# MMCSD2_CTL_CFG register map
Vendor: Texas Instruments
Registers are 16-bit, read-only, reset 0x0 unless marked. A register's access mark holds for its fields unless they carry their own. Offsets are as the file gives them; [hi:lo] are bit positions; lines under a group give offsets from that group.

## MMCSD2_CTL_CFG (part 3 of 3)
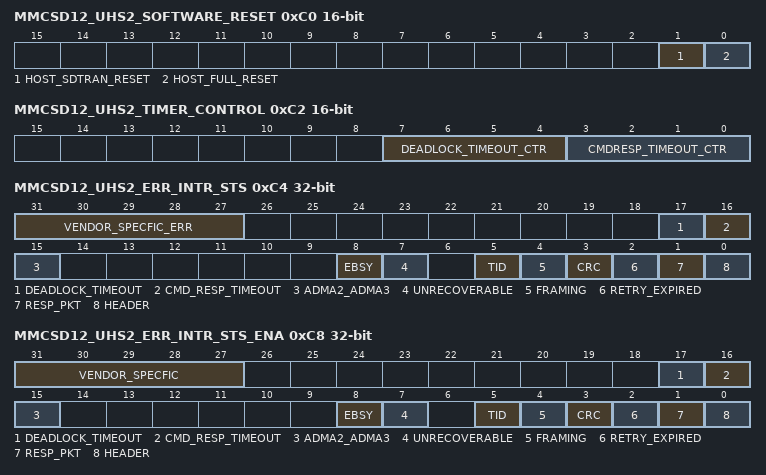
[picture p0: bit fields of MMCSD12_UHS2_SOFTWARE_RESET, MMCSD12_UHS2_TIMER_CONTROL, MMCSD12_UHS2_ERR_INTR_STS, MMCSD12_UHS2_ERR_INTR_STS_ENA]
0xC0 MMCSD12_UHS2_SOFTWARE_RESET access per field — UHS-II Software Reset Register.
  [1] HOST_SDTRAN_RESET rw — Host SD-TRAN Reset Host Driver set this bit to 1h to reset SD-TRAN layer when CMD0 is issued to Device or data transfer error occurs. This bit is cleared automatically at completion of SD-TRAN reset. If CMD0 is issued, SD-TRAN Initialization sequence from CMD8 is required to use UHS-II mode. Assuming that bus power is maintained and CM-TRAN Initialization is not required. Host Controller requires to do followings: (1) SD Clock Enable is maintained (continue to provide RCLK). (2) All setting register is maintained. (3) Internal sequencers are reset to just after power on be able to issue a command. (4) All Interrupt Status, Status Enable and Signal Enable are cleared. (5) Data transfer is terminated and data in buffer is discarded. 0h: Not Affected 1h: Reset SD-TRAN
  [0] HOST_FULL_RESET rw — Host Full Reset On issuing FULL_RESET CCMD, Host Driver set this bit to 1h to reset Host Controller. This bit is cleared automatically at completion of Host Controller reset. Initialization sequence from PHY Initialization is required to use UHS-II mode. Assuming that bus power is maintained. Host Controller requires to do followings: (1) SD Clock Enable is cleared (internal Clock is still synchronized). (2) All setting register is cleared. (3) Internal sequencers are reset to just after power on. (4) All Interrupt Status, Status Enable and Signal Enable are cleared. 0h: Not Affected 1h: Reset Host Controller
0xC2 MMCSD12_UHS2_TIMER_CONTROL access per field — UHS-II Timeout Control Register.
  [7:4] DEADLOCK_TIMEOUT_CTR rw — Timeout Counter Value for Deadlock This value determines the deadlock period while host expecting to receive a packet (1 second). Timeout clock frequency will be generated by dividing the base clock TMCLK value by this value. When setting this register, prevent inadvertent timeout events by clearing the Timeout for Deadlock (in the Fh: Reserved Eh: TMCLK x 2 .... .... 1h: TMCLK x 2 0h: TMCLK x 2
  [3:0] CMDRESP_TIMEOUT_CTR rw — Timeout Counter Value for CMD_RES This value determines the interval between command packet and response packet (5 ms). Timeout clock frequency will be generated by dividing the base clock TMCLK value by this value. When setting this register, prevent inadvertent timeout events by clearing the Timeout for CMD_RES (in the Fh: Reserved Eh: TMCLK x 2 .... .... 1h: TMCLK x 2 0h: TMCLK x 2
0xC4 MMCSD12_UHS2_ERR_INTR_STS 32-bit access not given — This register gives the status of all UHS-II interrupts.
  [31:27] VENDOR_SPECFIC_ERR — Vendor Specific Error Vendor may use this field for vendor specific error status. 0h: Interrupt is not generated 1h: Vendor Specific Error (access RW1C)
  [17] DEADLOCK_TIMEOUT — Timeout for Deadlock Setting of this bit means that deadlock timeout occurs. Host expects to receive a packet but not received in a specified timeout (1 second). Timeout value is determined by the setting of the 0h: Interrupt is not generated 1h: Deadlock Error (access RW1C)
  [16] CMD_RESP_TIMEOUT — Timeout for CMD_RES Setting of this bit means that RES Packet timeout occurs. Host expects to receive RES packet but not received in a specified timeout (5 ms). Timeout value is determined by the setting of the 0h: Interrupt is not generated 1h: RES Packet Timeout Error (access RW1C)
  [15] ADMA2_ADMA3 — ADMA2/3 Error Setting of this bit means that ADMA2/3 Error occurs in UHS-II mode. ADMA2/3 Error Status is indicated to the 0h: Interrupt is not generated 1h: ADMA2/3 Error (access RW1C)
  [8] EBSY — EBSY Error On receiving EBSY packet, if the packet indicates an error, this bit is set to 1h. Setting of this bit also sets Error Interrupt and Transfer Completer together in the 0h: Interrupt is not generated 1h: EBSY Error (Backend Error) (access RW1C)
  [7] UNRECOVERABLE — Unrecoverable Error Setting of this bit means that Unrecoverable Error is set in a packet from a device. 0h: Interrupt is not generated 1h: Device Unrecoverable Error (access RW1C)
  [5] TID — TID Error Setting of this bit means that TID Error occurs. 0h: Interrupt is not generated 1h: TID Error (access RW1C)
  [4] FRAMING — Framing Error Setting of this bit means that Framing Error occurs during a packet receiving. 0h: Interrupt is not generated 1h: Framing Error (access RW1C)
  [3] CRC — CRC Error Setting of this bit means that CRC Error occurs during a packet receiving. 0h: Interrupt is not generated 1h: CRC Error (access RW1C)
  [2] RETRY_EXPIRED — Retry Expired Setting of this bit means that Retry Counter Expired Error occurs during data transfer. If this bit is set, either Framing Error or CRC Error in this register shall be set. 0h: Interrupt is not generated 1h: Retry Expired Error (access RW1C)
  [1] RESP_PKT — RES Packet Error Host Controller Version 4.00 supports response error check function to avoid overhead of response error check by Host Driver during DMA execution. If the 0h: Interrupt is not generated 1h: RES Packet Error (access RW1C)
  [0] HEADER — Header Error Setting of this bit means that Header Error occurs in a received packet. 0h: Interrupt is not generated 1h: Header Error (access RW1C)
0xC8 MMCSD12_UHS2_ERR_INTR_STS_ENA 32-bit access per field — This register is used to enable the register fields.
  [31:27] VENDOR_SPECFIC rw — Vendor Specific Error Setting this bit to 1h enables setting of Vendor Specific Error bit in the 0h: Status is Disabled 1h: Status is Enabled
  [17] DEADLOCK_TIMEOUT rw — Timeout for Deadlock Setting this bit to 1h enables setting of Timeout for Dead lock bit in the 0h: Status is Disabled 1h: Status is Enabled
  [16] CMD_RESP_TIMEOUT rw — Timeout for CMD_RES Setting this bit to 1h enables setting of Timeout for CMD_RES bit in the 0h: Status is Disabled 1h: Status is Enabled
  [15] ADMA2_ADMA3 rw — ADMA2/3 Error Setting this bit to 1h enables setting of ADMA2/3 Error bit in the 0h: Status is Disabled 1h: Status is Enabled
  [8] EBSY rw — EBSY Error Setting this bit to 1h enables setting of EBSY Error bit in the 0h: Status is Disabled 1h: Status is Enabled
  [7] UNRECOVERABLE rw — Unrecoverable Error Setting this bit to 1h enables setting of Unrecoverable Error bit in the 0h: Status is Disabled 1h: Status is Enabled
  [5] TID rw — TID Error Setting this bit to 1h enables setting of TID Error bit in the 0h: Status is Disabled 1h: Status is Enabled
  [4] FRAMING rw — Framing Error Setting this bit to 1h enables setting of Framing Error bit in the 0h: Status is Disabled 1h: Status is Enabled
  [3] CRC rw — CRC Error Setting this bit to 1h enables setting of CRC Error bit in the 0h: Status is Disabled 1h: Status is Enabled
  [2] RETRY_EXPIRED rw — Retry Expired Setting this bit to 1h enables setting of Retry Expired bit in the 0h: Status is Disabled 1h: Status is Enabled
  [1] RESP_PKT rw — RES Packet Error Setting this bit to 1h enables setting of RES Packet Error bit in the 0h: Status is Disabled 1h: Status is Enabled
  [0] HEADER rw — Header Error Setting this bit to 1h enables setting of Header Error bit in the 0h: Status is Disabled 1h: Status is Enabled
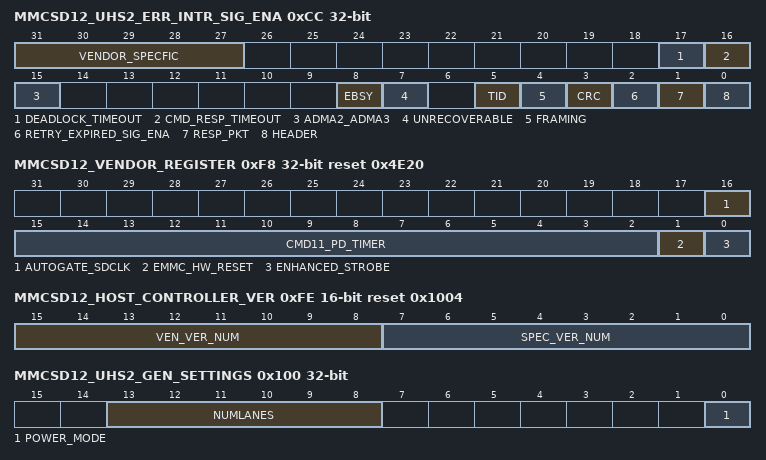
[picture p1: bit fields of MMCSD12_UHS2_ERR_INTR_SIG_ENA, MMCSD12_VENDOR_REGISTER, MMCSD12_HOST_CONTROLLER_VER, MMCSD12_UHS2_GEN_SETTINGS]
0xCC MMCSD12_UHS2_ERR_INTR_SIG_ENA 32-bit access per field — This register is used to generate UHS-II Interrupt signals.
  [31:27] VENDOR_SPECFIC rw — Vendor Specific Error Setting of a bit to 1h in this field enables generating interrupt signal when correspondent bit of Vendor Specific Error is set in the 0h: Interrupt Signal is Disabled 1h: Interrupt Signal is Enabled
  [17] DEADLOCK_TIMEOUT rw — Timeout for Deadlock Setting this bit to 1h enables generating interrupt signal when Timeout for Dead lock bit is set in the 0h: Interrupt Signal is Disabled 1h: Interrupt Signal is Enabled
  [16] CMD_RESP_TIMEOUT rw — Timeout for CMD_RES Setting this bit to 1h enables generating interrupt signal when Timeout for CMD_RES bit is set in the 0h: Interrupt Signal is Disabled 1h: Interrupt Signal is Enabled
  [15] ADMA2_ADMA3 rw — ADMA2/3 Error Setting this bit to 1h enables generating interrupt signal when ADMA2/3 Error bit is set in the 0h: Interrupt Signal is Disabled 1h: Interrupt Signal is Enabled
  [8] EBSY rw — EBSY Error Setting this bit to 1h enables generating interrupt signal when EBSY Error bit is set in the 0h: Interrupt Signal is Disabled 1h: Interrupt Signal is Enabled
  [7] UNRECOVERABLE rw — Unrecoverable Error Setting this bit to 1h enables generating interrupt signal when Unrecoverable Error bit is set in the 0h: Interrupt Signal is Disabled 1h: Interrupt Signal is Enabled
  [5] TID rw — TID Error Setting this bit to 1h enables generating interrupt signal when TID Error bit is set in the 0h: Interrupt Signal is Disabled 1h: Interrupt Signal is Enabled
  [4] FRAMING rw — Framing Error Setting this bit to 1h enables generating interrupt signal when Framing Error bit is set in the 0h: Interrupt Signal is Disabled 1h: Interrupt Signal is Enabled
  [3] CRC rw — CRC Error Setting this bit to 1h enables generating interrupt signal when CRC Error bit is set in the 0h: Interrupt Signal is Disabled 1h: Interrupt Signal is Enabled
  [2] RETRY_EXPIRED_SIG_ENA rw — Retry Expired Setting this bit to 1h enables generating interrupt signal when Retry Expired bit is set in the 0h: Interrupt Signal is Disabled 1h: Interrupt Signal is Enabled
  [1] RESP_PKT rw — RES Packet Error Setting this bit to 1h enables generating interrupt signal when RES Packet Error bit is set in the 0h: Interrupt Signal is Disabled 1h: Interrupt Signal is Enabled
  [0] HEADER rw — Header Error Setting this bit to 1h enables generating interrupt signal when Header Error bit is set in the 0h: Interrupt Signal is Disabled 1h: Interrupt Signal is Enabled
0xE0 MMCSD12_UHS2_SETTINGS_PTR reset 0x100 — This register is pointer for UHS-II settings.
  [15:0] UHS2_SETTINGS_PTR — Pointer for UHS-II Settings Register
0xE2 MMCSD12_UHS2_CAPABILITIES_PTR reset 0x110 — This register is pointer for UHS-II Capabilities Register.
  [15:0] UHS2_CAPABILITIES_PTR — Pointer for UHS-II Capabilities Register
0xE4 MMCSD12_UHS2_TEST_PTR reset 0x120 — This register is pointer for UHS-II Test Register.
  [15:0] UHS2_TEST_PTR — Pointer for UHS-II Test Register
0xE6 MMCSD12_SHARED_BUS_CTRL_PTR reset 0x130 — This register is pointer for UHS-II Shared Bus Control Register.
  [15:0] SHARED_BUS_CTRL_PTR — Pointer for Shared Bus Control Register
0xE8 MMCSD12_VENDOR_SPECFIC_PTR reset 0x140 — This register is pointer for UHS-II Vendor Specific Register.
  [15:0] VENDOR_SPECFIC_PTR — Pointer for Vendor Specific Area
0xF4 MMCSD12_BOOT_TIMEOUT_CONTROL 32-bit rw — This is used to program the boot timeout value counter.
  [31:0] DATA_TIMEOUT_CNT — Boot Data Timeout Counter Value This value determines the interval by which DAT line timeouts are detected during boot operation for eMMC4.4 card. The value is in number of SD clock.
0xF8 MMCSD12_VENDOR_REGISTER 32-bit access per field reset 0x4E20 — Vendor register added for Auto Gate SD CLK, CMD11 Power Down Timer, Enhanced Strobe and eMMC Hardware Reset.
  [16] AUTOGATE_SDCLK rw — Auto Gate SD CLK If this bit is set, SD CLK will be gated automatically when there is no transfer. This is applicable only for Embedded Device. 0h: Disable 1h: Enable
  [15:2] CMD11_PD_TIMER rw — CMD11 Power Down Timer Value
  [1] EMMC_HW_RESET rw — eMMC Hardware Reset Hardware reset signal is generared for eMMC card when this bit is set. 0h: De-sassert hardware reset pin 1h: Drives the hardware reset pin as ZERO (Active LOW to eMMC card)
  [0] ENHANCED_STROBE rw — Enhanced Strobe This bit enables the enhanced strobe logic of the Host Controller.
0xFC MMCSD12_SLOT_INT_STS — This register is used to read the interrupt signal for each slot.
  [7:0] INTR_SIG — Interrupt Signal for Slot#0 These status bits indicate the logical OR of Interrupt signal and Wakeup signal for each slot.
0xFE MMCSD12_HOST_CONTROLLER_VER reset 0x1004 — This register is used to read the vendor version number and specification version number.
  [15:8] VEN_VER_NUM — Vendor Version Number The Vendor Version Number is set to 10h (1.0)
  [7:0] SPEC_VER_NUM — Specification Version Number This status indicates the Host Controller Specification Version. The upper and lower 4-bits indicate the version. 0h: SD Host Controller Specification Version 1.00 1h: SD Host Controller Specification Version 2.00 Including the feature of the ADMA and Test Register 2h: SD Host Controller Specification Version 3.00 3h: SD Host Controller Specification Version 4.00 4h: SD Host Controller Specification Version 4.10 Others: Reserved
0x100 MMCSD12_UHS2_GEN_SETTINGS 32-bit access per field — Start Address of General settings is pointed by the Register.
  [13:8] NUMLANES rw — Number of Lanes and Functionalities The lane configuration of a Host System is set to this field depends on the capability among Host Controller and connected devices. 2 Lanes FD mode is mandatory and the others modes are optional. 0h: 2 Lanes FD or 2L-HD 1h: Not Used 2h: 3 Lanes 2D1U-FD (Embedded) 3h: 3 Lanes 1D2U-FD (Embedded) 4h: 4 Lanes 2D2U-FD (Embedded) Others: Reserved
  [0] POWER_MODE rw — Power Mode This field determines either Fast mode or Low Power mode. Host and all devices connected to the host shall be set to the same mode. 0h: Fast Mode 1h: Low Power Mode
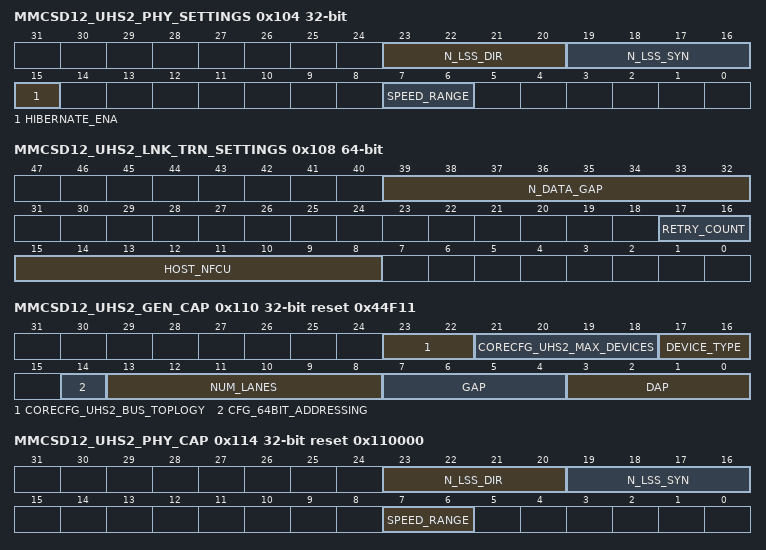
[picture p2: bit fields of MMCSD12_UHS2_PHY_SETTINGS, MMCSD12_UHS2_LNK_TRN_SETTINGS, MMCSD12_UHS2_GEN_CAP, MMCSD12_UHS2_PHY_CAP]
0x104 MMCSD12_UHS2_PHY_SETTINGS 32-bit access per field — Start Address of PHY settings is pointed by the Register.
  [23:20] N_LSS_DIR rw — Host N_LSS_DIR The largest value of N_LSS_DIR capabilities among the Host Controller and Connected Devices is set to this field. 0h: 8 x 16 LSS 1h: 8 x 1 LSS 2h: 8 x 2 LSS 3h: 8 x 3 LSS .... .... Fh: 8 x 15 LSS
  [19:16] N_LSS_SYN rw — Host N_LSS_SYN The largest value of N_LSS_SYN capabilities among the Host Controller and Connected Devices is set to this field. 0h: 4 x 16 LSS 1h: 4 x 1 LSS 2h: 4 x 2 LSS 3h - 4 x 3 LSS .... .... Fh: 4 x 15 LSS
  [15] HIBERNATE_ENA rw — Hibernate Enable After checking card capability of Hibernate mode, if all devices support Hibernate mode, this bit may be set. This bit determines whether Host remains in Dormant state or goes to Hibernate state. In Hibernate mode, VDD1 Power may be off. 0h: Hibernate Disabled 1h: Hibernate Enabled
  [7:6] SPEED_RANGE rw — Speed Range PLL multiplier is selected by this field. Change of PLL Multiplier is not effective immediately and is applied from exiting Dormant State. 0h: Range A (Defalt) 1h: Range B 2h: Reserved 3h: Reserved
0x108 MMCSD12_UHS2_LNK_TRN_SETTINGS 64-bit access per field — Start Address of LINK/TRAN settings is pointed by the Register.
  [39:32] N_DATA_GAP rw — Host N_DATA_GAP The largest value of N_DATA_GAP capabilities among the Host Controller and Connected Devices is set to this field. 00h: No Gap 01h: 1 LSS 02h: 2 LSS 03h: 3 LSS .... .... FFh: 255 LSS
  [17:16] RETRY_COUNT rw — Retry Count Data Burst retry count is set to this field. 00h: Retry Disabled 01h: 1 time 02h: 2 times 03h: 3 times
  [15:8] HOST_NFCU rw — Host N_FCU Host Driver sets the number of blocks in Data Burst (Flow Control) to this field. The value shall be smaller than or equal to N_FCU capabilities among the Host Controller and connected card and devices. Setting 1 to 4 blocks is recommended considering buffer size. 00h: 256 Blocks 01h: 1 Block 02h: 2 Blocks 03h: 3 Blocks .... .... FFh: 255 Blocks
0x110 MMCSD12_UHS2_GEN_CAP 32-bit reset 0x44F11 — Start Address of General Capabilities is pointed by the Register.
  [23:22] CORECFG_UHS2_BUS_TOPLOGY — Bus Topology This field indicates one of bus topologies configured by a Host system. 0h: P2P Connection 1h: Ring Connection 2h: HUB Connection 3h: HUB is Connected in Ring
  [21:18] CORECFG_UHS2_MAX_DEVICES — Number of Devices Supported This field indicates the maximum number of devices supported by the Host Controller. 0h: Not used 1h: 1 Devices 2h: 2 Devices .... .... Fh: 15 Devices
  [17:16] DEVICE_TYPE — Removable/Embedded This field indicates device type configured by a Host system. 0h: Removable Card (P2P) 1h: Embedded Devices 2h: Embedded Devices + Removable Card 3h: Reserved
  [14] CFG_64BIT_ADDRESSING — 64-bit Addressing This field indicates support of 64-bit addressing by the Host Controller. 0h: 32-bit Addressing is supported 1h: 32-bit and 64-bit Addressing is supported
  [13:8] NUM_LANES — Number of Lanes and Functionalities This field indicates support of lanes by the Host Controller. 0 mean not supported and 1 means supported. D08: 2L-HD D09: 2D1U-FD D10: 1D2U-FD D11: 2D2U-FD D12: Reserved D13: Reserved
  [7:4] GAP — GAP (Group Allocation Power) This field indicates the maximum capability of host power supply for a group configured by a Host system. This field is used to set the argument of DEVICE_INIT CCM. 0h: Not used 1h: 360 mW 2h: 720 mW .... .... Fh: 360 x 15 mW
  [3:0] DAP — DAP (Device Allocation Power) This field indicates the maximum capability of host power supply for a device configured by a Host system. This field is used to set the argument of DEVICE_INIT CCMD. 0h: 360 mW (Default) 1h: 360 mW 2h: 720 mW .... .... Fh: 360 x 15 mW
0x114 MMCSD12_UHS2_PHY_CAP 32-bit reset 0x110000 — Start Address of PHY Capabilities is pointed by the Register.
  [23:20] N_LSS_DIR — Host N_LSS_DIR This field indicates the minimum N_LSS_DIR required by the Host Controller. 0h: 4 x 16 LSS 1h: 4 x 1 LSS 2h: 4 x 2 LSS 3h: 4 x 3 LSS .... .... Fh: 4 x 15 LSS
  [19:16] N_LSS_SYN — Host N_LSS_SYN This field indicates the minimum N_LSS_SYN required by the Host Controller. 0h: 4 x 16 LSS 1h: 4 x 1 LSS 2h: 4 x 2 LSS 3h: 4 x 3 LSS .... .... Fh: 4 x 15 LSS
  [7:6] SPEED_RANGE — Speed Range This field indicates supported Speed Range by the Host Controller. 0h: Range A (Default) 1h: Range A and Range B 2h: Reserved 3h: Reserved
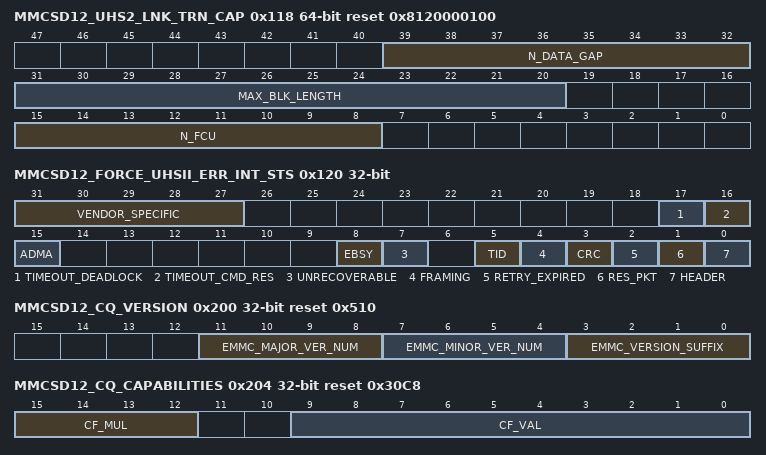
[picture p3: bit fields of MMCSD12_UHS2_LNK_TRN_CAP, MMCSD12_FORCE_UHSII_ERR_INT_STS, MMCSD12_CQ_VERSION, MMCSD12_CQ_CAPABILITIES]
0x118 MMCSD12_UHS2_LNK_TRN_CAP 64-bit reset 0x8120000100 — Start Address of LINK/TRAN settings is pointed by the Register.
  [39:32] N_DATA_GAP — Host N_DATA_GAP This field indicates the minimum number of data gap (DIDL) supported by the Host Controller. 00h: No Gap 01h: 1 LSS 02h: 2 LSS 03h: 3 LSS .... .... FFh: 255 LSS
  [31:20] MAX_BLK_LENGTH — Host Maximum Block Length This field indicates maximum block length by the Host Controller. 000h: Not Used 001h: 1 byte 002h: 2 bytes .... .... 200h: 512 bytes .... .... 800h: 2048 bytes 801h - FFFh: Not Used
  [15:8] N_FCU — Host N_FCU This field indicates maximum the number of blocks in a Flow Control unit by the Host Controller. This value is determined by supported buffer size. 00h: 256 Blocks 01h: 1 Block 02h: 2 Block 03h: 3 Block .... .... FFh: 255 Blocks
0x120 MMCSD12_FORCE_UHSII_ERR_INT_STS 32-bit access per field — This register is not physically implemented, rather it is an address where the register can be written.
  [31:27] VENDOR_SPECIFIC wo — Force Event for Vendor Specific Error 0h: Not Affected 1h: Vendor Specific Error Status is set
  [17] TIMEOUT_DEADLOCK wo — Force Event for Timeout for Deadlock Setting this bit forces the Host Controller to set Timeout for Deadlock in the 0h: Not affected 1h: Timeout for Deadlock Error status is set
  [16] TIMEOUT_CMD_RES wo — Force Event for Timeout for CMD_RES Setting this bit forces the Host Controller to set Timeout for CMD_RES in the 0h: Not affected 1h: Timout for CMD_RES Status is set
  [15] ADMA wo — Force Event for ADMA Error Setting this bit forces the Host Controller to set ADMA Error in the 0h: Not affected 1h: ADMA Error Status is set
  [8] EBSY wo — Force Event for EBSY Error Setting this bit forces the Host Controller to set EBSY Error in the 0h: Not affected 1h: EBSY Error Status is set
  [7] UNRECOVERABLE wo — Force Event for Unrecoverable Error Setting this bit forces the Host Controller to set Unrecoverable Error in the 0h: Not affected 1h: Unrecoverable Error Status is set
  [5] TID wo — Force Event for TID Error Setting this bit forces the Host Controller to set TID Error in the 0h: Not affected 1h: TID Error Status is set
  [4] FRAMING wo — Force Event for Framing Error Setting this bit forces the Host Controller to set Framing Error in the 0h: Not affected 1h: Framing Error Status is set
  [3] CRC wo — Force Event for CRC Error Setting this bit forces the Host Controller to set CRC Error in the 0h: Not affected 1h: CRC Error Status is set
  [2] RETRY_EXPIRED wo — Force Event for Retry Expired Setting this bit forces the Host Controller to set Retry Expired in the 0h: Not affected 1h: Retry expired error status is set
  [1] RES_PKT wo — Force Event for RES Packet Error Setting this bit forces the Host Controller to set RES Packet Error in the 0h: Not affected 1h: RES packet error status is set
  [0] HEADER wo — Force Event for Header Error Setting this bit forces the Host Controller to set Header Error in the 0h: Not affected 1h: Header error status is set
0x200 MMCSD12_CQ_VERSION 32-bit reset 0x510 — This register provides information about the version of the eMMC CQ (Command Queueing) standard which is 285 implemented by the CQE, in BCD format. The current version is rev 5.1. The following table describes the CQBASE+00h: Command Queueing Version.
  [11:8] EMMC_MAJOR_VER_NUM — eMMC Major Version Number (digit left of decimal point), in BCD format
  [7:4] EMMC_MINOR_VER_NUM — eMMC Minor Version Number (digit right of decimal point), in BCD format
  [3:0] EMMC_VERSION_SUFFIX — eMMC Version Suffix (2nd digit right of decimal point), in BCD format
0x204 MMCSD12_CQ_CAPABILITIES 32-bit reset 0x30C8 — This register is reserved for capability indication.
  [15:12] CF_MUL — ITCFMUL and ITCFVAL indicate the frequency of the clock used for interrupt coalescing timer and for determining the SQS polling period. See ITCFVAL definition for details ( Field Value Description: 0h: 0.001 MHz 1h: 0.01 MHz 2h: 0.1 MHz 3h: 1 MHz 4h: 10 MHz Other values are reserved
  [9:0] CF_VAL — ITCFMUL and ITCFVAL indicate the frequency of the clock used for interrupt coalescing timer and for determining the polling period when using periodic SEND_QUEUE_STATUS (CMD13) polling. The clock frequency is calculated as ITCFVAL × ITCFMUL. For example, to encode 19.2 MHz ITCFVAL shall be 192 × 0.1 MHz = 19.2 MHz
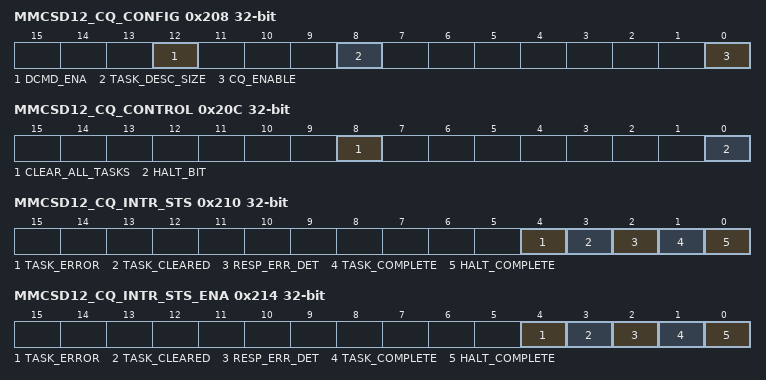
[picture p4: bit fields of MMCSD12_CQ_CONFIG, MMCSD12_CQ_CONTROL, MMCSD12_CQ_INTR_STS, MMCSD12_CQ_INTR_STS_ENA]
0x208 MMCSD12_CQ_CONFIG 32-bit access per field — This register controls CQE behavior affecting the general operation of command queueing 290 module or operation of multiple tasks in the same time.
  [12] DCMD_ENA rw — This bit indicates to the hardware whether the Task Descriptor in slot #31 of the TDL is a Data Transfer Task Descriptor, or a Direct Command Task Descriptor. CQE uses this bit when a task is issued in slot #31, to determine how to decode the Task Descriptor. Bit Value Description 0h: Task descriptor in slot #31 is a Data Transfer Task Descriptor 1h: Task descriptor in slot #31 is a DCMD Task Descriptor
  [8] TASK_DESC_SIZE rw — This bit indicates whether the task descriptor size is 128 bits or 64 bits. This bit can only be configured when the Bit Value Description 0h: Task descriptor size is 64 bits 1h: Task descriptor size is 128 bits
  [0] CQ_ENABLE rw — Software shall write 1h to this bit when in order to enable command queueing mode (enable CQE). When this bit is 0h, CQE is disabled and software controls the eMMC bus using the legacy eMMC host controller. Before software writes 1h to this bit, software shall verify that the eMMC host controller is in idle state and there are no commands or data transfers ongoing. When software wants to exit command queueing mode, it shall clear all previous tasks if such exist before setting this bit to 0h.
0x20C MMCSD12_CQ_CONTROL 32-bit access per field — This register controls CQE behavior affecting the general operation of command queueing 293 module or operation of multiple tasks in the same time.
  [8] CLEAR_ALL_TASKS rw — Software shall write 1h to this bit when it wants to clear all the tasks sent to the device. This bit can only be written when CQE is in halt state (Halt bit is 1h). When software writes 1h, the value of the register is updated to 1h, and CQE shall reset the Software should poll on this bit until it is set to back 0 and may then resume normal operation, by clearing the Halt bit. CQE does not communicate to the device that the tasks were cleared. It is softwares responsibility to order the device to discard the tasks in its queue using CMDQ_TASK_MGMT command. Writing 0h to this register shall have no effect.
  [0] HALT_BIT rw — Host software shall write 1h to the bit when it wants to acquire software control over the eMMC bus and disable CQE from issuing commands on the bus. For example, issuing a Discard Task command (CMDQ_TASK_MGMT). When software writes 1h, CQE shall complete the ongoing task if such a task is in progress. Once the task is completed and CQE is in idle state, CQE shall not issue new commands and shall indicate so to software by setting this bit to 1h. Software may poll on this bit until it is set to 1h, and may only then send commands on the eMMC bus. In order to exit halt state (resume CQE activity), software shall clear this bit (write 0h). Writing 0h when the value is already 0h shall have no effect.
0x210 MMCSD12_CQ_INTR_STS 32-bit access not given — This register indicates pending interrupts that require service. Each bit in this registers is asserted 296 in response a specific event, only if the respective bit is set in the register.
  [4] TASK_ERROR — This bit is asserted when task error is detected due to invalid task descriptor. (access RW1C)
  [3] TASK_CLEARED — This status bit is asserted (if (access RW1C)
  [2] RESP_ERR_DET — This status bit is asserted (if Software uses the (access RW1C)
  [1] TASK_COMPLETE — This status bit is asserted (if (1) A task is completed and the INT bit is set in its Task Descriptor (2) Interrupt caused by Interrupt Coalescing logic (access RW1C)
  [0] HALT_COMPLETE — This status bit is asserted (if (access RW1C)
0x214 MMCSD12_CQ_INTR_STS_ENA 32-bit access per field — This register enables and disables the reporting of the corresponding interrupt to host software in 299 register. When a bit is set (1h) and the corresponding interrupt condition is active, then the 300 bit in the register is asserted. Interrupt sources that are disabled (0h) are not indicated in the 301 register. This register is bit-index matched to the register.
  [4] TASK_ERROR rw — 1h: 0h:
  [3] TASK_CLEARED rw — 1h: 0h:
  [2] RESP_ERR_DET rw — 1h: 0h:
  [1] TASK_COMPLETE rw — 1h: 0h:
  [0] HALT_COMPLETE rw — 1h: 0h:
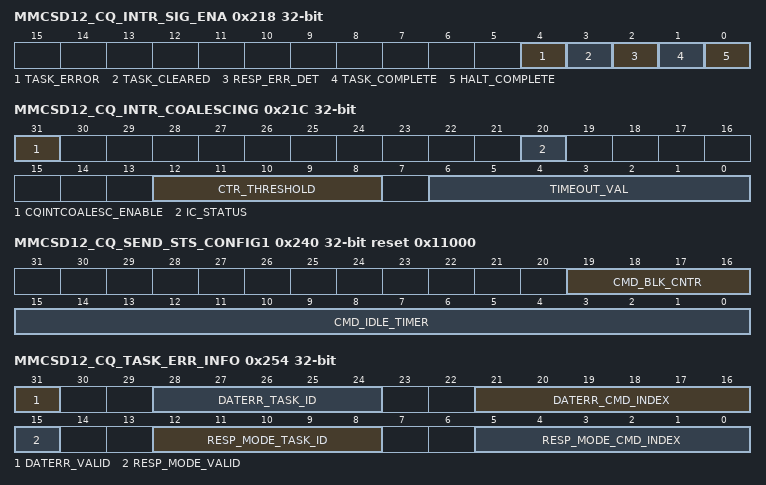
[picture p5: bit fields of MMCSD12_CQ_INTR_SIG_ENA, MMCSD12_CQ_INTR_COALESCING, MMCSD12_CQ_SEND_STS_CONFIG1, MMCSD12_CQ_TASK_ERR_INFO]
0x218 MMCSD12_CQ_INTR_SIG_ENA 32-bit access per field — This register enables and disables the generation of interrupts to host software. When a bit is set 304 (1h) and the corresponding bit in the register is set, then an interrupt is generated. Interrupt sources 305 that are disabled (0h) are still indicated in the register. This register is bit-index matched 306 to the register.
  [4] TASK_ERROR rw — When set and the
  [3] TASK_CLEARED rw — When set and the
  [2] RESP_ERR_DET rw — When set and the
  [1] TASK_COMPLETE rw — When set and the
  [0] HALT_COMPLETE rw — When set and the
0x21C MMCSD12_CQ_INTR_COALESCING 32-bit access per field — This register controls the interrupt coalescing feature.
  [31] CQINTCOALESC_ENABLE rw — When set to 0h by software, command responses are neither counted nor timed. Interrupts are still triggered by completion of tasks with INT = 1 in the Task Descriptor. When set to 1h, the interrupt coalescing mechanism is enabled and coalesced interrupts are generated.
  [20] IC_STATUS ro — This bit indicates to software whether any tasks (with INT = 0) have completed and counted towards interrupt coalescing (ICSB is set if and only if IC counter &gt; 0). Bit Value Description 0h: No task completions have occurred since last counter reset (IC counter = 0) 1h: At least one task completion has been counted (IC counter &gt; 0)
  [12:8] CTR_THRESHOLD rw — Software uses this field to configure the number of task completions (only tasks with INT = 0 in the Task Descriptor) which are required in order to generate an interrupt. Counter Operation: As data transfer tasks with INT = 0 complete, they are counted by CQE. The counter is reset by software during the interrupt service routine. The counter stops counting when it reaches the value configured in ICCTH. The maximum allowed value is 31.
  [6:0] TIMEOUT_VAL rw — Software uses this field to configure the maximum time allowed between the completion of a task on the bus and the generation of an interrupt. Timer Operation: The timer is reset by software during the interrupt service routine. It starts running when a data transfer task with INT = 0 is completed, after the timer was reset. When the timer reaches the value configured in ICTOVAL field it generates an interrupt and stops. The timers unit is equal to 1024 clock periods of the clock whose frequency is specified in the Internal Timer Clock Frequency field in the The minimum value is 1h (1024 clock periods) and the maximum value is 7Fh (127 × 1024 clock periods). For example, a
0x220 MMCSD12_CQ_TDL_BASE_ADDR 32-bit rw — This register is used for configuring the lower 32 bits of the byte address of the head of the Task 312 Descriptor List in the host memory.
  [31:0] CQTDLBA_LO — This register stores the LSB bits (bits 31-0) of the byte address of the head of the Task Descriptor List in system memory. The size of the task descriptor list is 32 × (Task Descriptor size + Transfer Descriptor size) as configured by Host driver. This address shall be set on Byte1 KByte boundary. The lower 10 bits of this register shall be set to 0h by software and shall be ignored by CQE.
0x224 MMCSD12_CQ_TDL_BASE_ADDR_UPBITS 32-bit rw — This register is used for configuring the upper 32 bits of the byte address of the head of the Task 316 Descriptor List in the host memory.
  [31:0] CQTDLBA_HI — This register stores the MSB bits (bits 63-32) of the byte address of the head of the Task Descriptor List in system memory. The size of the task descriptor list is 32 × (Task Descriptor size + Transfer Descriptor size) as configured by Host driver. This register is reserved when using 32-bit addressing mode.
0x228 MMCSD12_CQ_TASK_DOOR_BELL 32-bit access not given — Using this register, software triggers CQE to process a new task.
  [31:0] CQTDB_VAL — Software shall configure the Writing 1h to bit n of this register triggers CQE to start processing the task encoded in slot n of the TDL. CQE always processes tasks in-order according to the order submitted to the list by the CQE processes Data Transfer tasks by reading the Task Descriptor and sending QUEUED_TASK_PARAMS (CMD44) and QUEUED_TASK_ADDRESS (CMD45) commands to the device. CQE processes DCMD tasks (in slot #31, when enabled) by reading the Task Descriptor, and generating the command encoded by its index and argument. The corresponding bit is cleared to 0h by CQE in one of the following events: (a) When a task execution is completed (with success or error) (b) The task is cleared using (c) All tasks are cleared using (d) CQE is disabled using Software may initiate multiple tasks at the same time (batch submission) by writing 1h to multiple bits of this register in the same transaction. In the case of batch submission: CQE shall process the tasks in order of the task index, starting with the lowest index. If one or more tasks in the batch are marked with QBR, the ordering of execution will be based on said processing order. Writing 0h by software shall have no impact on the hardware, and will not change the value of the register bit. (access W1S)
0x22C MMCSD12_CQ_TASK_COMP_NOTIF 32-bit access not given — This register is used by CQE to notify software about completed tasks.
  [31:0] CQTCN_VAL — CQE shall set bit n of this register (at the same time it clears bit n of the When receiving interrupt for task completion, software may read this register to know which tasks have finished. After reading this register, software may clear the relevant bit fields by writing 1h to the corresponding bits. (access RW1C)
0x230 MMCSD12_CQ_DEV_QUEUE_STATUS 32-bit — This register stores the most recent value of the device's queue status.
  [31:0] CQDQ_STS — Every time the Host controller receives a queue status register (QSR) from the device, it updates this register with the response of status command (the device's queue status).
0x234 MMCSD12_CQ_DEV_PENDING_TASKS 32-bit — This register indicates to software which tasks are queued in the device, awaiting execution.
  [31:0] CQDP_TSKS — Bit n of this register is set if and only if QUEUED_TASK_PARAMS (CMD44) and QUEUED_TASK_ADDRESS (CMD45) were sent for this specific task and if this task hasnt been executed yet. CQE shall set this bit after receiving a successful response for CMD45. CQE shall clear this bit after the task has completed execution. Software needs to read this register in the task-discard procedure, when the controller is halted, to determine if the task is queued in the device. If the task is queued, the driver sends a CMDQ_TASK_MGMT (CMD48) to the device ordering it to discard the task. Then software clears the task in the CQE. Only then the software orders CQE to resume its operation using
0x238 MMCSD12_CQ_TASK_CLEAR 32-bit rw — This register is used for removing an outstanding task in the CQE 327. The register should be used only when CQE is in Halt state.
  [31:0] CQTCLR — Writing 1h to bit n of this register orders CQE to clear a task which software has previously issued. This bit can only be written when CQE is in Halt state as indicated in the When software writes 1h to a bit in this register, CQE updates the value to 1h, and starts clearing the data structures related to the task. CQE clears the bit fields (sets a value of 0h) in the Software should poll on the Writing to this register only clears the task in the CQE and does not have impact on the device. In order to discard the task in the device, host software shall send CMDQ_TASK _MGMT while CQE is still in Halt state. Host driver is not allowed to use this register to clear multiple tasks at the same time. Clearing multiple tasks can be done using Writing 0h to a register bit shall have no impact.
0x240 MMCSD12_CQ_SEND_STS_CONFIG1 32-bit access per field reset 0x11000 — The register controls when the SEND_QUEUE_STATUS commands are sent.
  [19:16] CMD_BLK_CNTR rw — This field indicates to CQE when to send SEND_QUEUE_STATUS (CMD13) command to inquire the status of the devices task queue. A value of n means CQE shall send status command on the CMD line, during the transfer of data block A value of 0h means that SEND_QUEUE_STATUS (CMD13) command shall not be sent during the transaction. Instead it will be sent only when the data lines are idle. A value of 1 means that STATUS command is to be sent during the last block of the transaction.
  [15:0] CMD_IDLE_TIMER rw — This field indicates to CQE the polling period to use when using periodic SEND_QUEUE_STATUS (CMD13) polling. Periodic polling is used when tasks are pending in the device, but no data transfer is in progress. When a SEND_QUEUE_STATUS response indicating that no task is ready for execution, CQE counts the configured time until it issues the next SEND_QUEUE_STATUS. Timer units are clock periods of theclock whose frequency is specified in the Internal Timer Clock Frequency field in the The minimum value is 1h (1 clock period) and the maximum value is FFFFh (65535 clock periods). Default interval is: 4096 clock periods. For example, a
0x244 MMCSD12_CQ_SEND_STS_CONFIG2 32-bit access per field — This register is used for 333 configuring RCA field in SEND_QUEUE_STATUS command argument.
  [15:0] QUEUE_RCA rw — This field provides CQE with the contents of the 16-bit RCA field in SEND_QUEUE_STATUS (CMD13) command argument. CQE shall copy this field to bits 31-16 of the argument when transmitting SEND_QUEUE_STATUS (CMD13) command.
0x248 MMCSD12_CQ_DCMD_RESPONSE 32-bit — This register is used for passing the response of a DCMD task to software.
  [31:0] LAST_RESP — This register contains the response of the command generated by the last direct command (DCMD) task which was sent. CQE shall update this register when it receives the response for a DCMD task. This register is considered valid only after bit 31 of the
0x250 MMCSD12_CQ_RESP_ERR_MASK 32-bit reset 0xFDF9A080 — This register controls the generation of Response Error Detection (RED) interrupt.
  [31:0] CQRMEM — This bit is used as in interrupt mask on the device status filed which is received in R1/R1b responses. Bit Value Description (for any bit i): 1h: When a R1/R1b response is received, with bit i in the device status set, a RED interrupt is generated 0h: When a R1/R1b response is received, bit i in the device status is ignored The reset value of this register is set to trigger an interrupt on all 'Error' type bits in the device status.
0x254 MMCSD12_CQ_TASK_ERR_INFO 32-bit — This register is updated by CQE when an error occurs on data or command related to a task activity. When such error is detected by CQE or indicated by the eMMC controller CQE stores in the register the task IDs and the command indices of the commands which were executed on the 343 command line and data lines when the error occurred. Software is expected to use this information in the error recovery procedure.
  [31] DATERR_VALID — This bit is updated when an error is detected by CQE, or indicated by eMMC controller. If a data transfer is in progress when the error is detected/indicated, the bit is set to 1h. If a no data transfer is in progress when the error is detected/indicated, the bit is cleared to 0h.
  [28:24] DATERR_TASK_ID — This field indicates the ID of the task which was executed on the data lines when an error occurred. The field is updated if a data transfer is in progress when an error is detected by CQE, or indicated by eMMC controller.
  [21:16] DATERR_CMD_INDEX — This field indicates the index of the command which was executed on the data lines when an error occurred. The index shall be set to EXECUTE_READ_TASK (CMD46) or EXECUTE_WRITE_TASK (CMD47) according to the data direction. The field is updated if a data transfer is in progress when an error is detected by CQE, or indicated by eMMC controller.
  [15] RESP_MODE_VALID — This bit is updated when an error is detected by CQE, or indicated by eMMC controller. If a command transaction is in progress when the error is detected/indicated, the bit is set to 1h. If a no command transaction is in progress when the error is detected/indicated, the bit is cleared to 0h.
  [12:8] RESP_MODE_TASK_ID — This field indicates the ID of the task which was executed on the command line when an error occurred. The field is updated if a command transaction is in progress when an error is detected by CQE, or indicated by eMMC controller.
  [5:0] RESP_MODE_CMD_INDEX — This field indicates the index of the command which was executed on the command line when an error occurred. The field is updated if a command transaction is in progress when an error is detected by CQE, or indicated by eMMC controller.
0x258 MMCSD12_CQ_CMD_RESP_INDEX 32-bit — This register stores the index of the last received command response.
  [5:0] LAST_CRI — This field stores the index of the last received command response. CQE shall update the value every time a command response is received.
0x25C MMCSD12_CQ_CMD_RESP_ARG 32-bit — This register stores the index of the last received command response.
  [31:0] LAST_CRA — This field stores the argument of the last received command. CQE shall update the value every time a command response is received.
0x260 MMCSD12_CQ_ERROR_TASK_ID 32-bit — CQ Error Task ID Register
  [4:0] TERR_ID — Task Error ID
